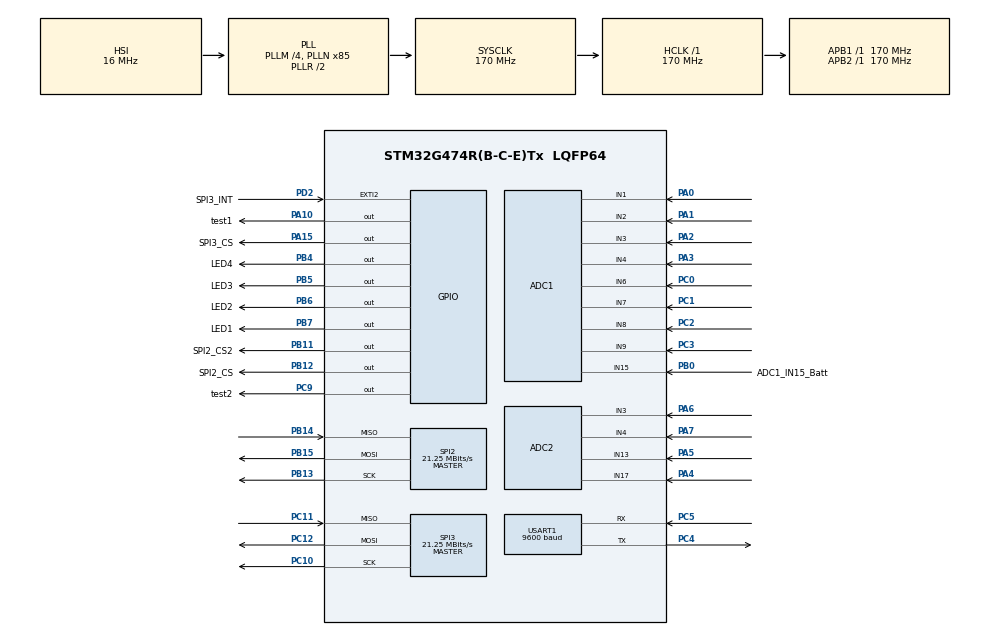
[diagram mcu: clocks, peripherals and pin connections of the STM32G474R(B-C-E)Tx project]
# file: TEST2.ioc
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ADC1.Channel-0\#ChannelRegularConversion=ADC_CHANNEL_3
ADC1.Channel-1\#ChannelRegularConversion=ADC_CHANNEL_2
ADC1.Channel-2\#ChannelRegularConversion=ADC_CHANNEL_1
ADC1.Channel-3\#ChannelRegularConversion=ADC_CHANNEL_9
ADC1.Channel-4\#ChannelRegularConversion=ADC_CHANNEL_15
ADC1.Channel-5\#ChannelRegularConversion=ADC_CHANNEL_8
ADC1.Channel-6\#ChannelRegularConversion=ADC_CHANNEL_7
ADC1.Channel-7\#ChannelRegularConversion=ADC_CHANNEL_6
ADC1.Channel-8\#ChannelRegularConversion=ADC_CHANNEL_4
ADC1.ContinuousConvMode=ENABLE
ADC1.DMAContinuousRequests=ENABLE
ADC1.EnableAnalogWatchDog1=false
ADC1.NbrOfConversion=9
ADC1.NbrOfConversionFlag=1
ADC1.OffsetNumber-0\#ChannelRegularConversion=ADC_OFFSET_NONE
ADC1.OffsetNumber-1\#ChannelRegularConversion=ADC_OFFSET_NONE
ADC1.OffsetNumber-2\#ChannelRegularConversion=ADC_OFFSET_NONE
ADC1.OffsetNumber-3\#ChannelRegularConversion=ADC_OFFSET_NONE
ADC1.OffsetNumber-4\#ChannelRegularConversion=ADC_OFFSET_NONE
ADC1.OffsetNumber-5\#ChannelRegularConversion=ADC_OFFSET_NONE
ADC1.OffsetNumber-6\#ChannelRegularConversion=ADC_OFFSET_NONE
ADC1.OffsetNumber-7\#ChannelRegularConversion=ADC_OFFSET_NONE
ADC1.OffsetNumber-8\#ChannelRegularConversion=ADC_OFFSET_NONE
ADC1.Rank-0\#ChannelRegularConversion=1
ADC1.Rank-1\#ChannelRegularConversion=2
ADC1.Rank-2\#ChannelRegularConversion=3
ADC1.Rank-3\#ChannelRegularConversion=4
ADC1.Rank-4\#ChannelRegularConversion=5
ADC1.Rank-5\#ChannelRegularConversion=6
ADC1.Rank-6\#ChannelRegularConversion=7
ADC1.Rank-7\#ChannelRegularConversion=8
ADC1.Rank-8\#ChannelRegularConversion=9
ADC1.SamplingTime-0\#ChannelRegularConversion=ADC_SAMPLETIME_640CYCLES_5
ADC1.SamplingTime-1\#ChannelRegularConversion=ADC_SAMPLETIME_640CYCLES_5
ADC1.SamplingTime-2\#ChannelRegularConversion=ADC_SAMPLETIME_640CYCLES_5
ADC1.SamplingTime-3\#ChannelRegularConversion=ADC_SAMPLETIME_640CYCLES_5
ADC1.SamplingTime-4\#ChannelRegularConversion=ADC_SAMPLETIME_640CYCLES_5
ADC1.SamplingTime-5\#ChannelRegularConversion=ADC_SAMPLETIME_640CYCLES_5
ADC1.SamplingTime-6\#ChannelRegularConversion=ADC_SAMPLETIME_640CYCLES_5
ADC1.SamplingTime-7\#ChannelRegularConversion=ADC_SAMPLETIME_640CYCLES_5
ADC1.SamplingTime-8\#ChannelRegularConversion=ADC_SAMPLETIME_640CYCLES_5
ADC1.master=1
ADC2.Channel-0\#ChannelRegularConversion=ADC_CHANNEL_17
ADC2.Channel-1\#ChannelRegularConversion=ADC_CHANNEL_13
ADC2.Channel-2\#ChannelRegularConversion=ADC_CHANNEL_3
ADC2.Channel-3\#ChannelRegularConversion=ADC_CHANNEL_4
ADC2.ContinuousConvMode=ENABLE
ADC2.DMAContinuousRequests=ENABLE
ADC2.NbrOfConversion=4
ADC2.NbrOfConversionFlag=1
ADC2.OffsetNumber-0\#ChannelRegularConversion=ADC_OFFSET_NONE
ADC2.OffsetNumber-1\#ChannelRegularConversion=ADC_OFFSET_NONE
ADC2.OffsetNumber-2\#ChannelRegularConversion=ADC_OFFSET_NONE
ADC2.OffsetNumber-3\#ChannelRegularConversion=ADC_OFFSET_NONE
ADC2.Rank-0\#ChannelRegularConversion=1
ADC2.Rank-1\#ChannelRegularConversion=2
ADC2.Rank-2\#ChannelRegularConversion=3
ADC2.Rank-3\#ChannelRegularConversion=4
ADC2.SamplingTime-0\#ChannelRegularConversion=ADC_SAMPLETIME_640CYCLES_5
ADC2.SamplingTime-1\#ChannelRegularConversion=ADC_SAMPLETIME_640CYCLES_5
ADC2.SamplingTime-2\#ChannelRegularConversion=ADC_SAMPLETIME_640CYCLES_5
ADC2.SamplingTime-3\#ChannelRegularConversion=ADC_SAMPLETIME_640CYCLES_5
Dma.ADC1.0.Direction=DMA_PERIPH_TO_MEMORY
Dma.ADC1.0.EventEnable=DISABLE
Dma.ADC1.0.Instance=DMA1_Channel1
Dma.ADC1.0.MemDataAlignment=DMA_MDATAALIGN_HALFWORD
Dma.ADC1.0.MemInc=DMA_MINC_ENABLE
Dma.ADC1.0.Mode=DMA_CIRCULAR
Dma.ADC1.0.PeriphDataAlignment=DMA_PDATAALIGN_HALFWORD
Dma.ADC1.0.PeriphInc=DMA_PINC_DISABLE
Dma.ADC1.0.Polarity=HAL_DMAMUX_REQ_GEN_RISING
Dma.ADC1.0.Priority=DMA_PRIORITY_LOW
Dma.ADC1.0.RequestNumber=1
Dma.ADC1.0.SignalID=NONE
Dma.ADC1.0.SyncEnable=DISABLE
Dma.ADC1.0.SyncPolarity=HAL_DMAMUX_SYNC_NO_EVENT
Dma.ADC1.0.SyncRequestNumber=1
Dma.ADC1.0.SyncSignalID=NONE
Dma.ADC2.1.Direction=DMA_PERIPH_TO_MEMORY
Dma.ADC2.1.EventEnable=DISABLE
Dma.ADC2.1.Instance=DMA1_Channel2
Dma.ADC2.1.MemDataAlignment=DMA_MDATAALIGN_HALFWORD
Dma.ADC2.1.MemInc=DMA_MINC_ENABLE
Dma.ADC2.1.Mode=DMA_CIRCULAR
Dma.ADC2.1.PeriphDataAlignment=DMA_PDATAALIGN_HALFWORD
Dma.ADC2.1.PeriphInc=DMA_PINC_DISABLE
Dma.ADC2.1.Polarity=HAL_DMAMUX_REQ_GEN_RISING
Dma.ADC2.1.Priority=DMA_PRIORITY_LOW
Dma.ADC2.1.RequestNumber=1
Dma.ADC2.1.SignalID=NONE
Dma.ADC2.1.SyncEnable=DISABLE
Dma.ADC2.1.SyncPolarity=HAL_DMAMUX_SYNC_NO_EVENT
Dma.ADC2.1.SyncRequestNumber=1
Dma.ADC2.1.SyncSignalID=NONE
Dma.Request0=ADC1
Dma.Request1=ADC2
Mcu.Family=STM32G4
Mcu.Name=STM32G474R(B-C-E)Tx
Mcu.Package=LQFP64
NVIC.DMA1_Channel1_IRQn=true\:0\:0\:false\:false\:true\:false\:true\:true
NVIC.DMA1_Channel2_IRQn=true\:0\:0\:false\:false\:true\:false\:true\:true
NVIC.PriorityGroup=NVIC_PRIORITYGROUP_4
NVIC.RCC_IRQn=true\:0\:0\:false\:false\:true\:true\:false\:true
NVIC.USART1_IRQn=true\:0\:0\:false\:false\:true\:true\:true\:true
PA0.Mode=IN1-Single-Ended
PA0.Signal=ADC1_IN1
PA1.Mode=IN2-Single-Ended
PA1.Signal=ADC1_IN2
PA10.GPIO_Label=test1
PA10.Signal=GPIO_Output
PA13.Mode=Serial_Wire
PA13.Signal=SYS_JTMS-SWDIO
PA14.Mode=Serial_Wire
PA14.Signal=SYS_JTCK-SWCLK
PA15.GPIO_Label=SPI3_CS
PA15.Signal=GPIO_Output
PA2.Mode=IN3-Single-Ended
PA2.Signal=ADC1_IN3
PA3.Mode=IN4-Single-Ended
PA3.Signal=ADC1_IN4
PA4.Mode=IN17-Single-Ended
PA4.Signal=ADC2_IN17
PA5.Mode=IN13-Single-Ended
PA5.Signal=ADC2_IN13
PA6.Mode=IN3-Single-Ended
PA6.Signal=ADC2_IN3
PA7.Mode=IN4-Single-Ended
PA7.Signal=ADC2_IN4
PB0.GPIO_Label=ADC1_IN15_Batt
PB0.Mode=IN15-Single-Ended
PB0.Signal=ADC1_IN15
PB11.GPIO_Label=SPI2_CS2
PB11.Signal=GPIO_Output
PB12.GPIO_Label=SPI2_CS
PB12.Signal=GPIO_Output
PB13.Mode=Full_Duplex_Master
PB13.Signal=SPI2_SCK
PB14.Mode=Full_Duplex_Master
PB14.Signal=SPI2_MISO
PB15.Mode=Full_Duplex_Master
PB15.Signal=SPI2_MOSI
PB4.GPIO_Label=LED4
PB4.Signal=GPIO_Output
PB5.GPIO_Label=LED3
PB5.Signal=GPIO_Output
PB6.GPIO_Label=LED2
PB6.Signal=GPIO_Output
PB7.GPIO_Label=LED1
PB7.Signal=GPIO_Output
PC0.Mode=IN6-Single-Ended
PC0.Signal=ADC1_IN6
PC1.Mode=IN7-Single-Ended
PC1.Signal=ADC1_IN7
PC10.Mode=Full_Duplex_Master
PC10.Signal=SPI3_SCK
PC11.Mode=Full_Duplex_Master
PC11.Signal=SPI3_MISO
PC12.Mode=Full_Duplex_Master
PC12.Signal=SPI3_MOSI
PC2.Mode=IN8-Single-Ended
PC2.Signal=ADC1_IN8
PC3.Mode=IN9-Single-Ended
PC3.Signal=ADC1_IN9
PC4.Mode=Asynchronous
PC4.Signal=USART1_TX
PC5.Mode=Asynchronous
PC5.Signal=USART1_RX
PC8.GPIO_Label=PWM_T_TIM3_CH3
PC8.Signal=S_TIM3_CH3
PC9.GPIO_Label=test2
PC9.Signal=GPIO_Output
PD2.GPIO_Label=SPI3_INT
PD2.Signal=GPXTI2
PF0-OSC_IN.Mode=HSE-External-Oscillator
PF0-OSC_IN.Signal=RCC_OSC_IN
PF1-OSC_OUT.Mode=HSE-External-Oscillator
PF1-OSC_OUT.Signal=RCC_OSC_OUT
ProjectManager.HeapSize=0x200
ProjectManager.StackSize=0x400
ProjectManager.TargetToolchain=STM32CubeIDE
RCC.ADC12Freq_Value=170000000
RCC.ADC345Freq_Value=170000000
RCC.AHBFreq_Value=170000000
RCC.APB1Freq_Value=170000000
RCC.APB1TimFreq_Value=170000000
RCC.APB2Freq_Value=170000000
RCC.APB2TimFreq_Value=170000000
RCC.CortexFreq_Value=170000000
RCC.EXTERNAL_CLOCK_VALUE=12288000
RCC.HCLKFreq_Value=170000000
RCC.HSE_VALUE=24000000
RCC.HSI48_VALUE=48000000
RCC.HSI_VALUE=16000000
RCC.LSE_VALUE=32768
RCC.PLLM=RCC_PLLM_DIV4
RCC.PLLN=85
RCC.SYSCLKFreq_VALUE=170000000
RCC.SYSCLKSource=RCC_SYSCLKSOURCE_PLLCLK
RCC.USBFreq_Value=170000000
RCC.VCOOutputFreq_Value=340000000
SH.S_TIM3_CH3.0=TIM3_CH3
SPI2.BaudRatePrescaler=SPI_BAUDRATEPRESCALER_8
SPI2.CalculateBaudRate=21.25 MBits/s
SPI2.DataSize=SPI_DATASIZE_8BIT
SPI2.Direction=SPI_DIRECTION_2LINES
SPI2.Mode=SPI_MODE_MASTER
SPI2.VirtualType=VM_MASTER
SPI3.BaudRatePrescaler=SPI_BAUDRATEPRESCALER_8
SPI3.CalculateBaudRate=21.25 MBits/s
SPI3.DataSize=SPI_DATASIZE_8BIT
SPI3.Direction=SPI_DIRECTION_2LINES
SPI3.Mode=SPI_MODE_MASTER
SPI3.VirtualType=VM_MASTER
USART1.BaudRate=9600
USART1.VirtualMode-Asynchronous=VM_ASYNC
VP_SYS_VS_DBSignals.Mode=DisableDeadBatterySignals
board=custom

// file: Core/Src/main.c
/* USER CODE BEGIN Header */
/**
  ******************************************************************************
  * @file           : main.c
  * @brief          : Main program body
  ******************************************************************************
  * @attention
  *
  * Copyright (c) 2025 STMicroelectronics.
  * All rights reserved.
  *
  * This software is licensed under terms that can be found in the LICENSE file
  * in the root directory of this software component.
  * If no LICENSE file comes with this software, it is provided AS-IS.
  *
  ******************************************************************************
  */
/* USER CODE END Header */
#include "main.h"
#include "adc.h"
#include "dma.h"
#include "spi.h"
#include "usart.h"
#include "gpio.h"

void SystemClock_Config(void);

int main(void)
{

  /* MCU Configuration--------------------------------------------------------*/

  /* Reset of all peripherals, Initializes the Flash interface and the Systick. */
  HAL_Init();

  /* Configure the system clock */
  SystemClock_Config();

  /* Initialize all configured peripherals */
  MX_GPIO_Init();
  MX_DMA_Init();
  MX_ADC1_Init();
  MX_SPI2_Init();
  MX_ADC2_Init();
  MX_SPI3_Init();
  MX_USART1_UART_Init();
  /* USER CODE BEGIN 2 */
uint32_t last_time = HAL_GetTick();
  /* USER CODE END 2 */

  /* Infinite loop */
  while (1)
  {
	  if(HAL_GetTick() > (last_time + 2000))
	  {
		  last_time = HAL_GetTick();
		  HAL_GPIO_TogglePin(test1_GPIO_Port, test1_Pin);
		  HAL_GPIO_TogglePin(test2_GPIO_Port, test2_Pin);
		  HAL_GPIO_TogglePin(LED2_GPIO_Port, LED2_Pin);

	  }

  }
}

void SystemClock_Config(void)
{
  RCC_OscInitTypeDef RCC_OscInitStruct = {0};
  RCC_ClkInitTypeDef RCC_ClkInitStruct = {0};

  /** Configure the main internal regulator output voltage
  */
  HAL_PWREx_ControlVoltageScaling(PWR_REGULATOR_VOLTAGE_SCALE1_BOOST);

  /** Initializes the RCC Oscillators according to the specified parameters
  * in the RCC_OscInitTypeDef structure.
  */
  RCC_OscInitStruct.OscillatorType = RCC_OSCILLATORTYPE_HSI;
  RCC_OscInitStruct.HSIState = RCC_HSI_ON;
  RCC_OscInitStruct.HSICalibrationValue = RCC_HSICALIBRATION_DEFAULT;
  RCC_OscInitStruct.PLL.PLLState = RCC_PLL_ON;
  RCC_OscInitStruct.PLL.PLLSource = RCC_PLLSOURCE_HSI;
  RCC_OscInitStruct.PLL.PLLM = RCC_PLLM_DIV4;
  RCC_OscInitStruct.PLL.PLLN = 85;
  RCC_OscInitStruct.PLL.PLLP = RCC_PLLP_DIV2;
  RCC_OscInitStruct.PLL.PLLQ = RCC_PLLQ_DIV2;
  RCC_OscInitStruct.PLL.PLLR = RCC_PLLR_DIV2;
  if (HAL_RCC_OscConfig(&RCC_OscInitStruct) != HAL_OK)
  {
    Error_Handler();
  }

  /** Initializes the CPU, AHB and APB buses clocks
  */
  RCC_ClkInitStruct.ClockType = RCC_CLOCKTYPE_HCLK|RCC_CLOCKTYPE_SYSCLK
                              |RCC_CLOCKTYPE_PCLK1|RCC_CLOCKTYPE_PCLK2;
  RCC_ClkInitStruct.SYSCLKSource = RCC_SYSCLKSOURCE_PLLCLK;
  RCC_ClkInitStruct.AHBCLKDivider = RCC_SYSCLK_DIV1;
  RCC_ClkInitStruct.APB1CLKDivider = RCC_HCLK_DIV1;
  RCC_ClkInitStruct.APB2CLKDivider = RCC_HCLK_DIV1;

  if (HAL_RCC_ClockConfig(&RCC_ClkInitStruct, FLASH_LATENCY_4) != HAL_OK)
  {
    Error_Handler();
  }
}

void Error_Handler(void)
{
  __disable_irq();
  while (1)
  {
  }
}
